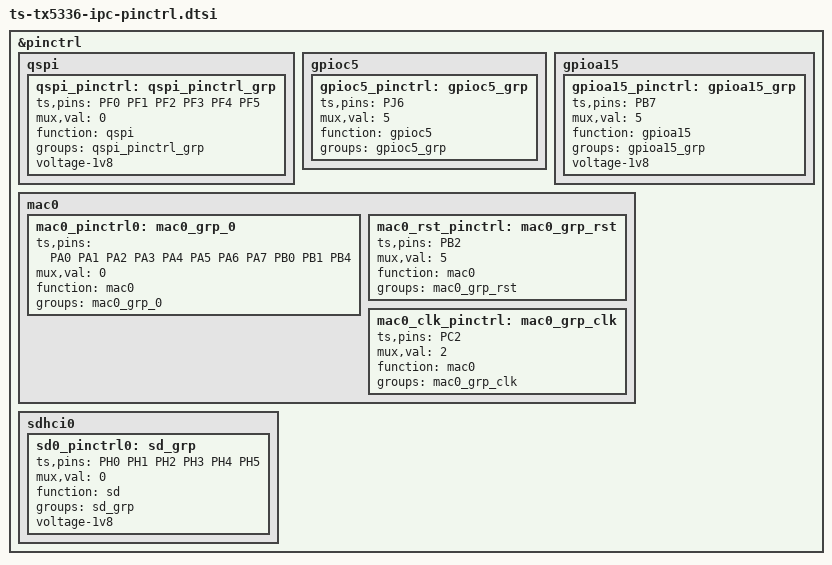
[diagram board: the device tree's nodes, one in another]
// SPDX-License-Identifier: GPL-2.0+
/*
 * dts file for tsingmicro dt53
 *
 * Copyright 2022 Beijing Tsingmicro Intelligent Technology Co.,Ltd.
 *
 */
#include <dt-bindings/pinctrl/pinctrl-ts-tx5336.h>

&pinctrl {

    qspi {
        qspi_pinctrl: qspi_pinctrl_grp {
            ts,pins = <PF0 PF1 PF2 PF3 PF4 PF5>;
            mux,val = <0>;
            function = "qspi";
            groups = "qspi_pinctrl_grp";        
            voltage-1v8;
        };
    };

	gpioc5 {
      gpioc5_pinctrl: gpioc5_grp {
            ts,pins = <PJ6>;
            mux,val = <5>;
            function = "gpioc5";
            groups = "gpioc5_grp";
        };
    };

    gpioa15 {
        gpioa15_pinctrl: gpioa15_grp {
            ts,pins = <PB7>;
            mux,val = <5>;
            function = "gpioa15";
            groups = "gpioa15_grp";
            voltage-1v8;
        };
    };

    mac0 {
		//MAC_EPHY_CLK MAC_TXCLK MAC_TXEN MAC_TXD0 MAC_TXD1 MAC_RXDV MAC_RXD0 MAC_RXD1
		//MAC_MDC MAC_MDIO  MAC_RXCLK
		mac0_pinctrl0: mac0_grp_0 {
			ts,pins = <PA0 PA1 PA2 PA3 PA4 PA5 PA6 PA7
					   PB0 PB1 PB4>;
			mux,val = <0>;
			function = "mac0";
			groups = "mac0_grp_0";
		};
		//GPIOB15
		mac0_rst_pinctrl: mac0_grp_rst {
			ts,pins = <PB2>;
			mux,val = <5>;
			function = "mac0";
			groups = "mac0_grp_rst";
		};
		//CHIPOUTCLK1
		mac0_clk_pinctrl: mac0_grp_clk {
			ts,pins = <PC2>;
			mux,val = <2>;
			function = "mac0";
			groups = "mac0_grp_clk";
		};
	};


	sdhci0 {
		sd0_pinctrl0: sd_grp {
			ts,pins = <PH0 PH1 PH2 PH3 PH4 PH5>;
			mux,val = <0>;
			function = "sd";
			groups = "sd_grp";
			voltage-1v8;
		};
	};


};
